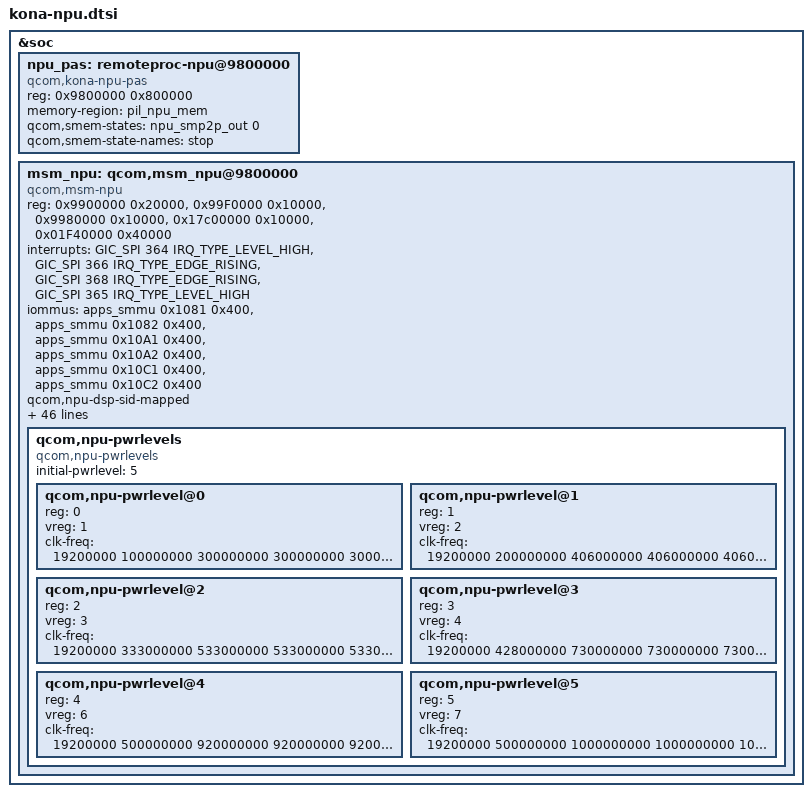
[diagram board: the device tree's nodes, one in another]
// SPDX-License-Identifier: GPL-2.0-only
/*
 * kona NPU, ported from the 4.19 kona-npu.dtsi / kona-v2.dtsi / kona.dtsi
 * (qcom,npu@9800000 PIL node) to the 5.15 drivers:
 *   - npu_pas:  qcom_q6v5_pas "qcom,kona-npu-pas" (npu.mdt, PAS 23) replaces
 *               the qcom,pil-tz-generic node.  No auto boot: msm_npu boots it
 *               through qcom,rproc-handle when userspace enables the fw.
 *   - msm_npu:  npu_v2 (CONFIG_MSM_NPU_V2).  The 4.19 devbw phandles
 *               (qcom,npubw-devs / qcom,src-dst-ports) become the three
 *               interconnect paths npu_v2 looks up by name.
 * The npu smp2p edge (kona-smp2p.dtsi) and npu_smp2p_out live there; its
 * mailbox goes through msm_npu's IPCC bridge, as on 4.19.
 */

#include <dt-bindings/clock/qcom,npucc-sm8250.h>
#include <dt-bindings/interconnect/qcom,kona.h>
#include <dt-bindings/interrupt-controller/arm-gic.h>
#include <dt-bindings/regulator/qcom,rpmh-regulator-levels.h>
#include <dt-bindings/soc/qcom,ipcc.h>

&soc {
	npu_pas: remoteproc-npu@9800000 {
		compatible = "qcom,kona-npu-pas";
		reg = <0x9800000 0x800000>;
		status = "ok";

		memory-region = <&pil_npu_mem>;

		/* Outputs to npu */
		qcom,smem-states = <&npu_smp2p_out 0>;
		qcom,smem-state-names = "stop";
	};

	msm_npu: qcom,msm_npu@9800000 {
		compatible = "qcom,msm-npu";
		status = "ok";
		reg = <0x9900000 0x20000>,
			<0x99F0000 0x10000>,
			<0x9980000 0x10000>,
			<0x17c00000 0x10000>,
			<0x01F40000 0x40000>;
		reg-names = "tcm", "core", "cc", "apss_shared", "tcsr";
		interrupts = <GIC_SPI 364 IRQ_TYPE_LEVEL_HIGH>,
				<GIC_SPI 366 IRQ_TYPE_EDGE_RISING>,
				<GIC_SPI 368 IRQ_TYPE_EDGE_RISING>,
				<GIC_SPI 365 IRQ_TYPE_LEVEL_HIGH>;
		interrupt-names = "error_irq", "wdg_bite_irq", "ipc_irq",
					"general_irq";
		iommus = <&apps_smmu 0x1081 0x400>, <&apps_smmu 0x1082 0x400>,
			<&apps_smmu 0x10A1 0x400>, <&apps_smmu 0x10A2 0x400>,
			<&apps_smmu 0x10C1 0x400>, <&apps_smmu 0x10C2 0x400>;
		qcom,npu-dsp-sid-mapped;
		qcom,rproc-handle = <&npu_pas>;

		clocks = <&npucc NPU_CC_XO_CLK>,
				<&npucc NPU_CC_CORE_CLK>,
				<&npucc NPU_CC_CAL_HM0_CLK>,
				<&npucc NPU_CC_CAL_HM1_CLK>,
				<&npucc NPU_CC_CAL_HM0_CDC_CLK>,
				<&npucc NPU_CC_CAL_HM1_CDC_CLK>,
				<&npucc NPU_CC_NOC_AXI_CLK>,
				<&npucc NPU_CC_NOC_AHB_CLK>,
				<&npucc NPU_CC_NOC_DMA_CLK>,
				<&npucc NPU_CC_LLM_CLK>,
				<&npucc NPU_CC_LLM_XO_CLK>,
				<&npucc NPU_CC_LLM_TEMP_CLK>,
				<&npucc NPU_CC_LLM_CURR_CLK>,
				<&npucc NPU_CC_DL_LLM_CLK>,
				<&npucc NPU_CC_ISENSE_CLK>,
				<&npucc NPU_CC_DPM_CLK>,
				<&npucc NPU_CC_DPM_XO_CLK>,
				<&npucc NPU_CC_DL_DPM_CLK>,
				<&npucc NPU_CC_RSC_XO_CLK>,
				<&npucc NPU_CC_DPM_TEMP_CLK>,
				<&npucc NPU_CC_CAL_HM0_DPM_IP_CLK>,
				<&npucc NPU_CC_CAL_HM1_DPM_IP_CLK>,
				<&npucc NPU_CC_S2P_CLK>,
				<&npucc NPU_CC_BWMON_CLK>,
				<&npucc NPU_CC_CAL_HM0_PERF_CNT_CLK>,
				<&npucc NPU_CC_CAL_HM1_PERF_CNT_CLK>,
				<&npucc NPU_CC_BTO_CORE_CLK>,
				<&npucc NPU_DSP_CORE_CLK_SRC>;
		clock-names = "xo_clk",
				"npu_core_clk",
				"cal_hm0_clk",
				"cal_hm1_clk",
				"cal_hm0_cdc_clk",
				"cal_hm1_cdc_clk",
				"axi_clk",
				"ahb_clk",
				"dma_clk",
				"llm_clk",
				"llm_xo_clk",
				"llm_temp_clk",
				"llm_curr_clk",
				"dl_llm_clk",
				"isense_clk",
				"dpm_clk",
				"dpm_xo_clk",
				"dl_dpm_clk",
				"rsc_xo_clk",
				"dpm_temp_clk",
				"cal_hm0_dpm_ip_clk",
				"cal_hm1_dpm_ip_clk",
				"s2p_clk",
				"bwmon_clk",
				"cal_hm0_perf_cnt_clk",
				"cal_hm1_perf_cnt_clk",
				"bto_core_clk",
				"dsp_core_clk_src";

		vdd-supply = <&npu_core_gdsc>;
		vdd_cx-supply = <&VDD_CX_LEVEL>;
		qcom,proxy-reg-names ="vdd", "vdd_cx";
		qcom,vdd_cx-uV-uA = <RPMH_REGULATOR_LEVEL_TURBO 100000>;
		resets = <&npucc NPU_CC_DPM_TEMP_CLK_ARES>,
				<&npucc NPU_CC_LLM_CURR_CLK_ARES>,
				<&npucc NPU_CC_LLM_TEMP_CLK_ARES>;
		reset-names = "dpm_temp_clk", "llm_curr_clk", "llm_temp_clk";
		#cooling-cells = <2>;
		mboxes = <&ipcc_mproc IPCC_CLIENT_NPU
				IPCC_MPROC_SIGNAL_GLINK_QMP>,
			<&ipcc_mproc IPCC_CLIENT_NPU
				IPCC_MPROC_SIGNAL_SMP2P>,
			<&ipcc_mproc IPCC_CLIENT_NPU
				IPCC_MPROC_SIGNAL_PING>;
		mbox-names = "ipcc-glink", "ipcc-smp2p", "ipcc-ping";
		#mbox-cells = <2>;
		interconnects = <&compute_noc MASTER_NPU &gem_noc SLAVE_LLCC>,
				<&mc_virt MASTER_LLCC &mc_virt SLAVE_EBI1>,
				<&compute_noc MASTER_NPU &mc_virt SLAVE_EBI1>;
		interconnect-names = "icc_llcc_bw", "icc_llcc_ddr_bw",
				"icc_dsp_ddr_bw";

		/*
		 * kona v2 levels (4.19 kona-v2.dtsi).  The 5.15 npucc-sm8250
		 * frequency tables are the v2 ones, so there is no v1 set here.
		 */
		qcom,npu-pwrlevels {
			#address-cells = <1>;
			#size-cells = <0>;
			compatible = "qcom,npu-pwrlevels";
			initial-pwrlevel = <5>;
			qcom,npu-pwrlevel@0 {
				reg = <0>;
				vreg = <1>;
				clk-freq = <19200000
					100000000
					300000000
					300000000
					300000000
					300000000
					200000000
					40000000
					300000000
					100000000
					19200000
					50000000
					50000000
					100000000
					100000000
					100000000
					19200000
					100000000
					19200000
					50000000
					200000000
					200000000
					50000000
					19200000
					300000000
					300000000
					19200000
					300000000>;
			};

			qcom,npu-pwrlevel@1 {
				reg = <1>;
				vreg = <2>;
				clk-freq = <19200000
					200000000
					406000000
					406000000
					406000000
					406000000
					267000000
					40000000
					403000000
					200000000
					19200000
					50000000
					50000000
					200000000
					200000000
					200000000
					19200000
					200000000
					19200000
					50000000
					406000000
					406000000
					50000000
					19200000
					406000000
					406000000
					19200000
					400000000>;
			};

			qcom,npu-pwrlevel@2 {
				reg = <2>;
				vreg = <3>;
				clk-freq = <19200000
					333000000
					533000000
					533000000
					533000000
					533000000
					403000000
					75000000
					533000000
					214000000
					19200000
					50000000
					100000000
					214000000
					214000000
					214000000
					19200000
					214000000
					19200000
					50000000
					533000000
					533000000
					50000000
					19200000
					533000000
					533000000
					19200000
					500000000>;
			};

			qcom,npu-pwrlevel@3 {
				reg = <3>;
				vreg = <4>;
				clk-freq = <19200000
					428000000
					730000000
					730000000
					730000000
					730000000
					533000000
					75000000
					700000000
					300000000
					19200000
					100000000
					200000000
					300000000
					300000000
					300000000
					19200000
					300000000
					19200000
					100000000
					730000000
					730000000
					100000000
					19200000
					730000000
					730000000
					19200000
					660000000>;
			};

			qcom,npu-pwrlevel@4 {
				reg = <4>;
				vreg = <6>;
				clk-freq = <19200000
					500000000
					920000000
					920000000
					920000000
					920000000
					700000000
					75000000
					806000000
					300000000
					19200000
					100000000
					200000000
					300000000
					300000000
					300000000
					19200000
					300000000
					19200000
					100000000
					920000000
					920000000
					100000000
					19200000
					920000000
					920000000
					19200000
					800000000>;
			};

			qcom,npu-pwrlevel@5 {
				reg = <5>;
				vreg = <7>;
				clk-freq = <19200000
					500000000
					1000000000
					1000000000
					1000000000
					1000000000
					700000000
					75000000
					806000000
					300000000
					19200000
					100000000
					200000000
					300000000
					300000000
					300000000
					19200000
					300000000
					19200000
					100000000
					1000000000
					1000000000
					100000000
					19200000
					1000000000
					1000000000
					19200000
					800000000>;
			};
		};
	};
};
